# YC3122 register map
Series: ARMCM0; File version: 1.0
CPU: CM0 r1p0, little endian, no MPU, no FPU, 8 interrupt priority bits
Registers are 32-bit, read-write, reset 0x0 unless marked. A register's access mark holds for its fields unless they carry their own. Offsets are from the block's base; [hi:lo] are bit positions; {n}, {i} and the like mark numbered series.

## MIIC
Base 0x000F911C
Same registers: MI2C0 0x000F911C (alternate view of MIIC), MI2C1 0x000F921C
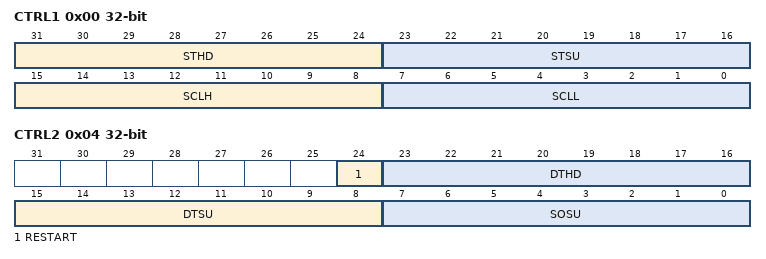
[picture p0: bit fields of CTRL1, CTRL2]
0x00 CTRL1
  [31:24] STHD — sthd 起始位保持时间
  [23:16] STSU — stsu 起始位建立时间
  [15:8] SCLH — sclh scl高电平时间
  [7:0] SCLL — scll scl低电平时间
0x04 CTRL2
  [24] RESTART — restart 注意！！！这一bit是控 制I2C协议中restart时序的,而不是复位I2C寄存 器；在写从设备的时候置0,在读从设备的时候要置1
  [23:16] DTHD — dthd 数据位的保持时间
  [15:8] DTSU — dtsu 数据位的建立时间
  [7:0] SOSU — sosu 停止位建立时间

## MBPK
Base 0x000FAC00
{0x0+4i} KEY[{i}] (i=0..31)
0x80 RST
  [0] RESET wo — 写1会复位KEY,BPK的配置,SENSOR的配 置。
0x84 CLR
  [3:0] CLR wo — 每一bit控制256-bit 的KEY清除 , 写“1”将清除相应的区域
0x88 LR
  [3:0] LOCK_READ — 每一bit控制256-bit 的KEY的锁定 , 写“1”将锁定读取相应的区域
0x8C LW
  [3:0] LOCK_WRITE — 每一bit控制256-bit 的KEY的锁定 , 写“1”将锁定写入相应的区域
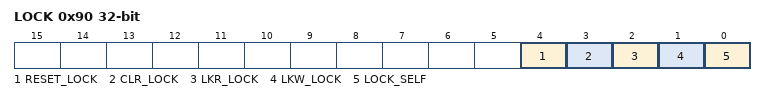
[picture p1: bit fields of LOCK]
0x90 LOCK
  [4] RESET_LOCK — 1:锁定RESET寄存器
  [3] CLR_LOCK — 1:锁定CLR寄存器
  [2] LKR_LOCK — 1:锁定LOCK_READ寄存器
  [1] LKW_LOCK — 1:锁定LOCK_WRITE寄存器
  [0] LOCK_SELF — 1:锁定LOCK寄存器本身(通常用于配置好其他的 锁定过后,且无法解锁)

## MRTC
Base 0x000FAF00
Same registers: MRTCLSI 0x000FAF00 (alternate view of MRTC), MRTCLSE 0x000FB000
0x00 EN
  [0] VAL — 1: 使能RTC 0:失能RTC
0x04 SEC_CNT
  [15:0] VAL — 设置一秒校准值
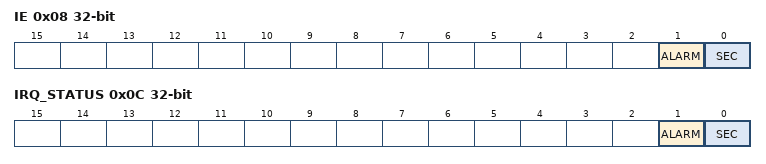
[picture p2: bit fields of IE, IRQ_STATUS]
0x08 IE
  [1] ALARM — 1: 允许闹钟中断 0:禁止闹钟中断
  [0] SEC — 1: 允许秒中断 0:禁止秒中断
0x0C IRQ_STATUS
  [1] ALARM — 1: 闹钟中断,clk_alm_ie为0时也会置 位,但不会触发中断
  [0] SEC — 1: 秒中断,scnd_ie为0时也会置位,但不 会触发中断
0x10 ALARM
  [31:0] IRQPREVAL — 闹钟中断预设值
0x14 TIME
  [31:0] VAL — 读操作读取当前RTC计数器值 写操作改写当前RTC计数器值,仅支持32-bit操作

## MADC
Base 0x000FBB00
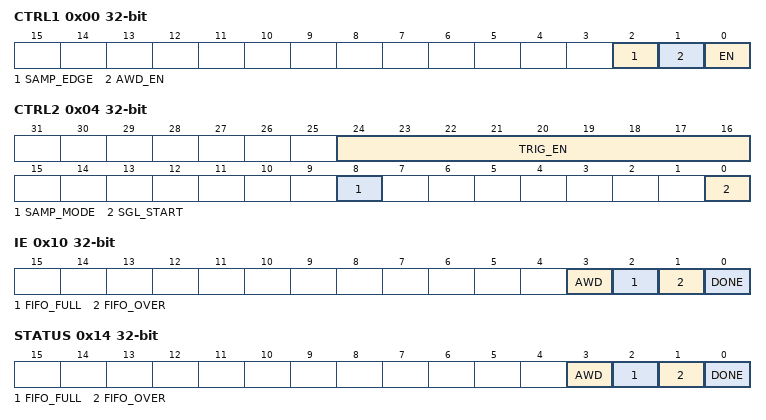
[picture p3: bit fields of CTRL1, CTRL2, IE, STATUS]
0x00 CTRL1
  [2] SAMP_EDGE — ADC采样边沿选择 0:下降沿采样 1: 上升沿采样
  [1] AWD_EN — ADC看门狗使能,ADC采样值超过看门狗门限时会 触发ADC看门狗中断 0::失能 1::使能
  [0] EN — adc模块数字开关 0: 失能ADC模块 1: 使能ADC模块
0x04 CTRL2
  [24:16] TRIG_EN — 定时器溢出触发ADC采样(仅适用于单次采样模式). 0:失能 1:使能
  [8] SAMP_MODE — 采样模式 0:单次采样模式 1:连续采样模式
  [0] SGL_START wo — 软件写'1',启动一次ADC采(仅在SAMP_M. ODE为0时生效)
0x10 IE
  [3] AWD — ADC看门狗中断使能 0:失能 1.使能
  [2] FIFO_FULL — FIFO数据溢出中断使能 0:失能 1.使能
  [1] FIFO_OVER — FIFO数据超过FIFO_LIMIT中断使能 0:失能 1.使能
  [0] DONE — 采样结束中断使能 0:失能 1.使能
0x14 STATUS
  [3] AWD — ADC看门狗中断状态,写1清除中断
  [2] FIFO_FULL — FIFO数据溢出中断状态,写1清除中断
  [1] FIFO_OVER — FIFO数据超过FIFO_LIMIT中断状态,写 1清除中断
  [0] DONE — 采样结束中断状态,写1清除中断
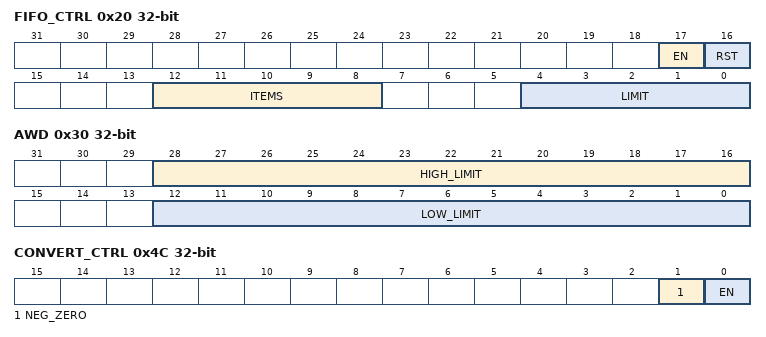
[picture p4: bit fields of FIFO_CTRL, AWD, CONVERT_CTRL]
0x20 FIFO_CTRL
  [17] EN — ADC FIFO使能 1:ADC数据有效转换值会写入FIFO. 0:ADC数据有效转换值不会写入FIFO
  [16] RST — ADC FIFO复位
  [12:8] ITEMS ro — FIFO中的有效数据量
  [4:0] LIMIT — 当LIMIT>0,且ITEMS>=LIMIT时触 发FIFO_OVER中断
0x24 FIFO
  [12:0] DATA ro — 使用FIFO时的ADC取数寄存器(未使能电压转换 功能时,读到的为原始AD值;使能电压转换功能时,读到的为 电压值的二进制补码,单位为mv)
0x28 DATA
  [12:0] VAL ro — 不使用FIFO时的ADC取数寄存器(未使能电压转 换功能时,读到的为原始AD值;使能电压转换功能时,读到的 为电压值的二进制补码,单位为mv)
0x30 AWD
  [28:16] HIGH_LIMIT — ADC看门狗的高阈值(使能电压转换时,需同时启用 负电压归零功能才能使用ADC看门狗功能)
  [12:0] LOW_LIMIT — ADC看门狗的低阈值(使能电压转换时,需同时启用 负电压归零功能才能使用ADC看门狗功能)
0x40 REF_AD
  [9:0] VAL — 基准电压AD值
0x44 REF_VOL
  [12:0] VAL — 基准电压(mV)
0x48 SLOPE
  [9:0] VAL — 电压转换斜率((vol_high-vol_low )/(vol_high_ref-vol_low_ref) )*64计算得到的10-bit整数值
0x4C CONVERT_CTRL
  [1] NEG_ZERO — 负电压归零控制(写1时,负电压以0V输出)
  [0] EN — 电压转换功能开关 1: 使能电压转换 0: 失能电压转换(输出原始ADC采样值)

## ANA_LDO_CLK — 32 ANA_LDO_CLK
Base 0x000FB200
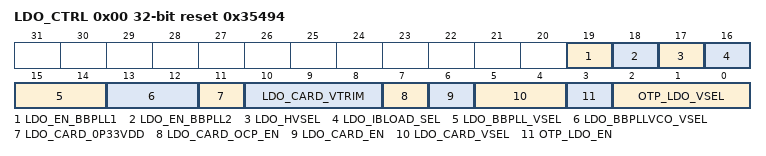
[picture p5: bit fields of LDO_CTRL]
0x00 LDO_CTRL reset 0x35494 — LDO control
  [19] LDO_EN_BBPLL1 — bbpll1 ldo enable
  [18] LDO_EN_BBPLL2 — bbpll2 ldo enable
  [17] LDO_HVSEL — bbpll ldo high voltage sel
  [16] LDO_IBLOAD_SEL — bbpll bleed current sel
  [15:14] LDO_BBPLL_VSEL — bbpll ldo output voltage select
  [13:12] LDO_BBPLLVCO_VSEL — bbpll vco ldo output voltage select
  [11] LDO_CARD_0P33VDD — 7816 sink LDO for GPIO floating ground pull down
  [10:8] LDO_CARD_VTRIM — 7816 LDO output voltage trim
  [7] LDO_CARD_OCP_EN — 7816 LDO over-current protection
  [6] LDO_CARD_EN — 7816 LDO enable
  [5:4] LDO_CARD_VSEL — 7816 LDO output voltage select
  [3] OTP_LDO_EN — OTP ldo25 enable
  [2:0] OTP_LDO_VSEL — OTP ldo25 voitage selction
